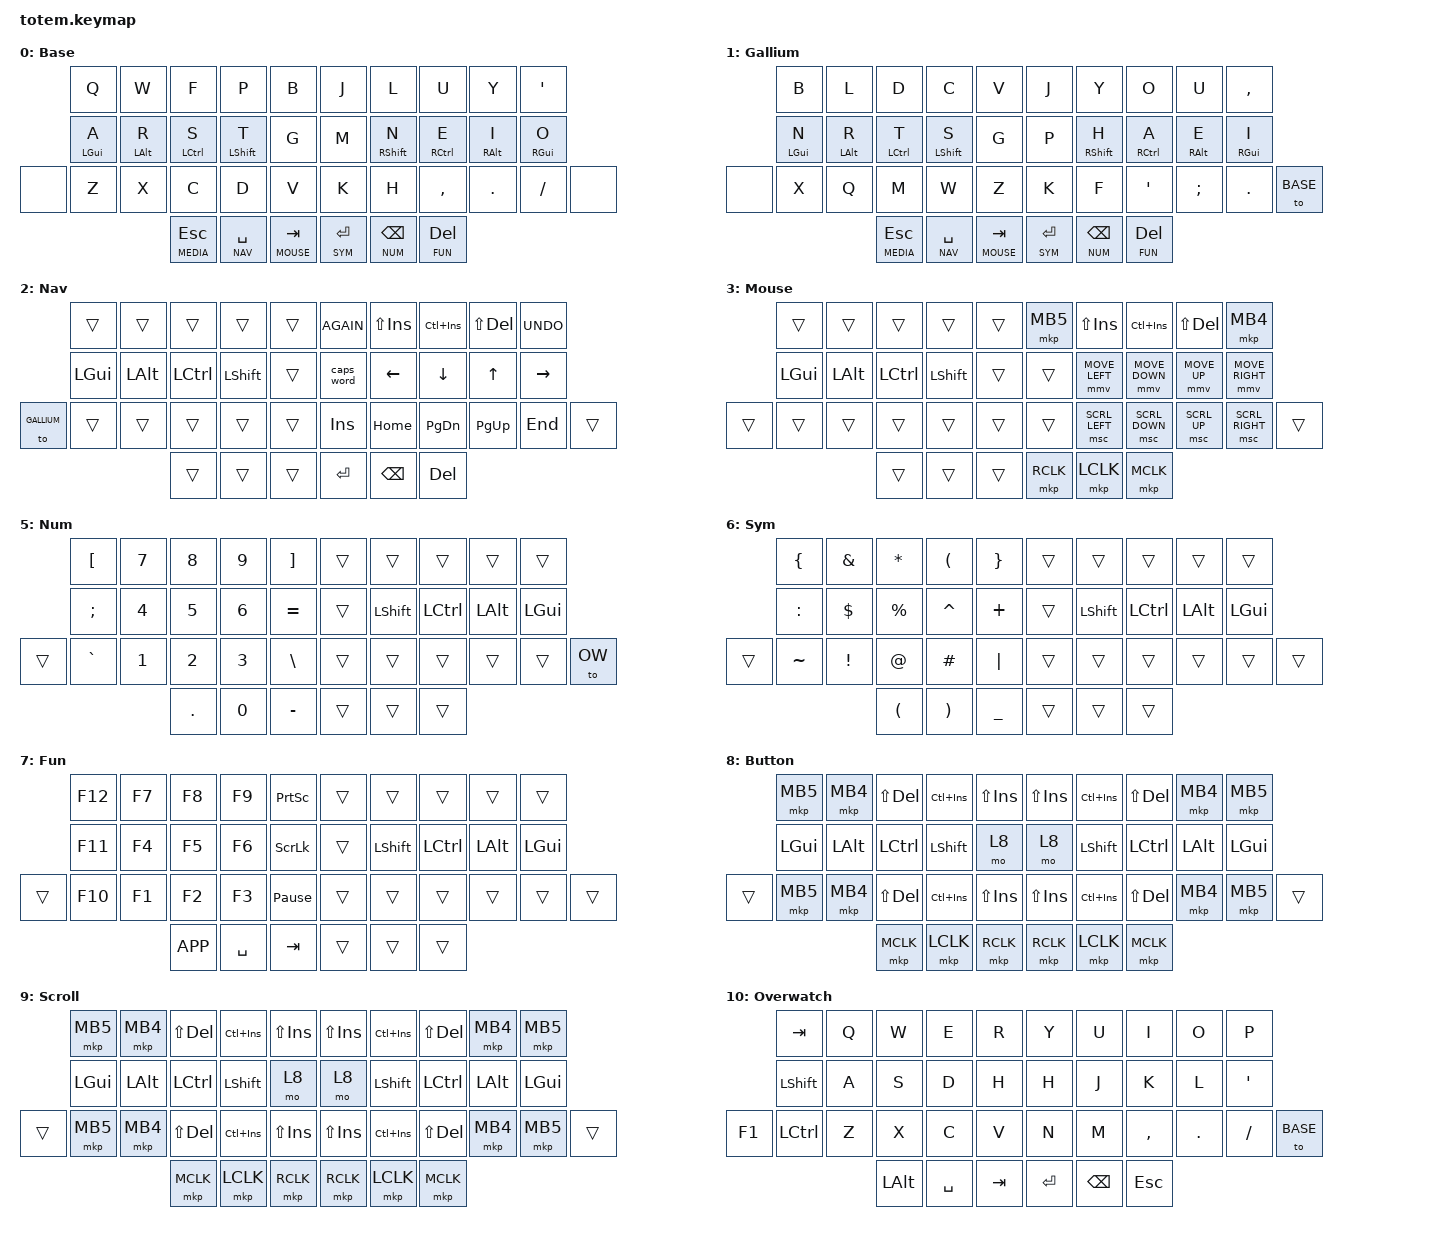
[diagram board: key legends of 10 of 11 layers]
//
//                                                        ▀▀▀▀▀     ▀▀▀▀▀          ▀▀█▀▀
//                                                        ▄▀▀▀▄  ▄  ▄▀▀▀▄  ▄  ▄▀▀▀▄  █  ▄▀▀▀▄
//                                                        █   █  █  █   █  █  █   █  █  █   █
//                                                         ▀▀▀   █   ▀▀▀   █   ▀▀▀   ▀   ▀▀▀
//                                                               █      ▄▄▄█▄▄▄    █   █  
//                                                               ▀      █  █  █     █▄█
//                                                             ▀▀▀▀▀    █  █  █      ▀
//                                                                      ▀  ▀  ▀
//
// ▄▄▄▄▄▄▄▄▄▄▄▄▄▄▄▄▄▄▄▄▄▄▄▄▄▄▄▄▄▄▄▄▄▄▄▄▄▄▄▄▄▄▄▄▄▄▄▄▄▄▄▄▄▄▄▄▄▄▄▄▄▄▄▄▄▄▄▄▄▄▄▄▄▄▄▄▄▄▄▄▄▄▄▄▄▄▄▄▄▄▄▄▄▄▄▄▄▄▄▄▄▄▄▄▄▄▄▄▄▄▄▄▄▄▄▄▄▄▄▄▄▄▄▄▄▄▄▄▄▄▄▄▄▄▄▄▄▄▄▄▄▄▄▄▄▄▄▄▄

#include <behaviors.dtsi>
#include <dt-bindings/zmk/keys.h>
#include <dt-bindings/zmk/pointing.h>
#include <dt-bindings/zmk/outputs.h>
#include <dt-bindings/zmk/bt.h>

#define BASE        0
#define GALLIUM     1
#define NAV         2
#define MOUSE       3
#define MEDIA       4
#define NUM         5
#define SYM         6
#define FUN         7
#define BUTTON      8
#define SCROLL      9
#define OW          10

// Key position definitions for 38-key Totem layout

#define KEYS_L 0 1 2 3 4 10 11 12 13 14 20 21 22 23 24 25  // left hand
#define KEYS_R 5 6 7 8 9 15 16 17 18 19 26 27 28 29 30 31  // right hand
#define THUMBS 32 33 34 35 36 37                           // thumbs

&mt {
    quick-tap-ms = <100>;
    global-quick-tap;
    flavor = "tap-preferred";
    tapping-term-ms = <170>;
};

&lt {
    tapping-term-ms = <240>;
    flavor = "balanced";
    quick-tap-ms = <150>;
};

/ {
    behaviors {
        // Timeless homerow mods for left hand
        // require-prior-idle-ms = 10500 / WPM (adjust based on typing speed)

        hml: homerow_mods_left {
            compatible = "zmk,behavior-hold-tap";
            label = "HOMEROW_MODS_LEFT";
            #binding-cells = <2>;
            flavor = "balanced";
            tapping-term-ms = <280>;
            quick-tap-ms = <175>;
            require-prior-idle-ms = <125>;
            bindings = <&kp>, <&kp>;

            hold-trigger-key-positions = <KEYS_R THUMBS>;
            hold-trigger-on-release;
        };

        // Timeless homerow mods for right hand
        // Urob's timeless config: opposite hand trigger only

        hmr: homerow_mods_right {
            compatible = "zmk,behavior-hold-tap";
            label = "HOMEROW_MODS_RIGHT";
            #binding-cells = <2>;
            flavor = "balanced";
            tapping-term-ms = <280>;
            quick-tap-ms = <175>;
            require-prior-idle-ms = <125>;
            bindings = <&kp>, <&kp>;

            hold-trigger-key-positions = <KEYS_L THUMBS>;
            hold-trigger-on-release;
        };

        usbout: output_toggle {
            compatible = "zmk,behavior-mod-morph";
            #binding-cells = <0>;
            bindings = <&out OUT_TOG>, <&out OUT_USB>;
            mods = <(MOD_LGUI|MOD_LSFT|MOD_RGUI|MOD_RSFT)>;
        };
    };

    combos {
        compatible = "zmk,combos";

        shift_caps_word_combo {
            bindings = <&caps_word>;
            key-positions = <13 16>;
            timeout-ms = <100>;
            require-prior-idle-ms = <150>;
        };
    };

    keymap {
        compatible = "zmk,keymap";

        base_layer {
            display-name = "Base";
            bindings = <
       &kp Q        &kp W        &kp F          &kp P          &kp B            &kp J        &kp L         &kp U         &kp Y        &kp SQT
       &hml LGUI A  &hml LALT R  &hml LCTRL S   &hml LSHFT T   &kp G            &kp M        &hmr RSHFT N  &hmr RCTRL E  &hmr RALT I  &hmr RGUI O
&none  &kp Z        &kp X        &kp C          &kp D          &kp V            &kp K        &kp H         &kp COMMA     &kp DOT      &kp SLASH   &none
                                 &lt MEDIA ESC  &lt NAV SPACE  &lt MOUSE TAB    &lt SYM RET  &lt NUM BSPC  &lt FUN DEL
            >;
        };

        gallium_layer {
            display-name = "Gallium";
            bindings = <
       &kp B        &kp L        &kp D          &kp C          &kp V            &kp J        &kp Y         &kp O         &kp U        &kp COMMA
       &hml LGUI N  &hml LALT R  &hml LCTRL T   &hml LSHFT S   &kp G            &kp P        &hmr RSHFT H  &hmr RCTRL A  &hmr RALT E  &hmr RGUI I
&none  &kp X        &kp Q        &kp M          &kp W          &kp Z            &kp K        &kp F         &kp SQT       &kp SEMI     &kp DOT     &to BASE
                                 &lt MEDIA ESC  &lt NAV SPACE  &lt MOUSE TAB    &lt SYM RET  &lt NUM BSPC  &lt FUN DEL
            >;
        };

        nav_layer {
            display-name = "Nav";
            bindings = <
            &trans    &trans    &trans     &trans     &trans    &kp K_AGAIN  &kp LS(INS)  &kp LC(INS)  &kp LS(DEL)  &kp K_UNDO
            &kp LGUI  &kp LALT  &kp LCTRL  &kp LSHFT  &trans    &caps_word   &kp LEFT     &kp DOWN     &kp UP       &kp RIGHT
&to GALLIUM &trans    &trans    &trans     &trans     &trans    &kp INS      &kp HOME     &kp PG_DN    &kp PG_UP    &kp END     &trans
                            &trans     &trans     &trans    &kp RET      &kp BSPC     &kp DEL
            >;
        };

        mouse_layer {
            display-name = "Mouse";
            bindings = <
        &trans    &trans    &trans     &trans     &trans    &mkp MB5        &kp LS(INS)     &kp LC(INS)     &kp LS(DEL)   &mkp MB4
        &kp LGUI  &kp LALT  &kp LCTRL  &kp LSHFT  &trans    &trans          &mmv MOVE_LEFT  &mmv MOVE_DOWN  &mmv MOVE_UP  &mmv MOVE_RIGHT
&trans  &trans    &trans    &trans     &trans     &trans    &trans          &msc SCRL_LEFT  &msc SCRL_DOWN  &msc SCRL_UP  &msc SCRL_RIGHT  &trans
                            &trans     &trans     &trans    &mkp RCLK       &mkp LCLK       &mkp MCLK
            >;
        };

        media_layer {
            display-name = "Media";
            bindings = <
        &trans    &trans    &trans     &trans     &trans    &trans      &trans        &trans        &trans        &bt BT_CLR
        &kp LGUI  &kp LALT  &kp LCTRL  &kp LSHFT  &trans    &trans      &kp C_PREV    &kp C_VOL_DN  &kp C_VOL_UP  &kp C_NEXT
&trans  &trans    &trans    &trans     &trans     &trans    &usbout     &bt BT_SEL 0  bt BT_SEL 1   bt BT_SEL 2   bt BT_SEL 3  &kp C_SLEEP
                            &trans     &trans     &trans    &kp C_STOP  &kp C_PP      &kp C_MUTE
            >;
        };

        num_layer {
            display-name = "Num";
            bindings = <
        &kp LBKT   &kp N7  &kp N8   &kp N9  &kp RBKT     &trans  &trans     &trans     &trans    &trans
        &kp SEMI   &kp N4  &kp N5   &kp N6  &kp EQUAL    &trans  &kp LSHFT  &kp LCTRL  &kp LALT  &kp LGUI
&trans  &kp GRAVE  &kp N1  &kp N2   &kp N3  &kp BSLH     &trans  &trans     &trans     &trans    &trans    &to OW
                           &kp DOT  &kp N0  &kp MINUS    &trans  &trans     &trans
            >;
        };

        sym_layer {
            display-name = "Sym";
            bindings = <
        &kp LBRC   &kp AMPS  &kp ASTRK  &kp LPAR   &kp RBRC     &trans  &trans     &trans     &trans    &trans
        &kp COLON  &kp DLLR  &kp PRCNT  &kp CARET  &kp PLUS     &trans  &kp LSHFT  &kp LCTRL  &kp LALT  &kp LGUI
&trans  &kp TILDE  &kp EXCL  &kp AT     &kp HASH   &kp PIPE     &trans  &trans     &trans     &trans    &trans    &trans
                             &kp LPAR   &kp RPAR   &kp UNDER    &trans  &trans     &trans
            >;
        };

        fun_layer {
            display-name = "Fun";
            bindings = <
        &kp F12  &kp F7  &kp F8     &kp F9     &kp PSCRN          &trans  &trans     &trans     &trans    &trans
        &kp F11  &kp F4  &kp F5     &kp F6     &kp SLCK           &trans  &kp LSHFT  &kp LCTRL  &kp LALT  &kp LGUI
&trans  &kp F10  &kp F1  &kp F2     &kp F3     &kp PAUSE_BREAK    &trans  &trans     &trans     &trans    &trans    &trans
                         &kp K_APP  &kp SPACE  &kp TAB            &trans  &trans     &trans
            >;
        };

        button_layer {
            display-name = "Button";
            bindings = <
        &mkp MB5  &mkp MB4  &kp LS(DEL)  &kp LC(INS)  &kp LS(INS)    &kp LS(INS)  &kp LC(INS)  &kp LS(DEL)  &mkp MB4  &mkp MB5
        &kp LGUI  &kp LALT  &kp LCTRL    &kp LSHFT    &mo 8          &mo 8        &kp LSHFT    &kp LCTRL    &kp LALT  &kp LGUI
&trans  &mkp MB5  &mkp MB4  &kp LS(DEL)  &kp LC(INS)  &kp LS(INS)    &kp LS(INS)  &kp LC(INS)  &kp LS(DEL)  &mkp MB4  &mkp MB5  &trans
                            &mkp MCLK    &mkp LCLK    &mkp RCLK      &mkp RCLK    &mkp LCLK    &mkp MCLK
            >;
        };

        scroll_layer {
            display-name = "Scroll";
            bindings = <
        &mkp MB5  &mkp MB4  &kp LS(DEL)  &kp LC(INS)  &kp LS(INS)    &kp LS(INS)  &kp LC(INS)  &kp LS(DEL)  &mkp MB4  &mkp MB5
        &kp LGUI  &kp LALT  &kp LCTRL    &kp LSHFT    &mo 8          &mo 8        &kp LSHFT    &kp LCTRL    &kp LALT  &kp LGUI
&trans  &mkp MB5  &mkp MB4  &kp LS(DEL)  &kp LC(INS)  &kp LS(INS)    &kp LS(INS)  &kp LC(INS)  &kp LS(DEL)  &mkp MB4  &mkp MB5  &trans
                            &mkp MCLK    &mkp LCLK    &mkp RCLK      &mkp RCLK    &mkp LCLK    &mkp MCLK
            >;
        };

        overwatch_layer {
            display-name = "Overwatch";
            bindings = <
       &kp TAB        &kp Q        &kp W          &kp E          &kp R            &kp Y        &kp U         &kp I         &kp O        &kp P
       &kp LSHIFT     &kp A        &kp S          &kp D          &kp H            &kp H        &kp J         &kp K         &kp L        &kp SQT
&kp F1 &kp LCTRL      &kp Z        &kp X          &kp C          &kp V            &kp N        &kp M         &kp COMMA     &kp DOT      &kp SLASH   &to BASE
                                   &kp LALT  &kp SPACE  &kp TAB    &kp RET  &kp BSPC  &kp ESC
            >;
        };

    };
};
